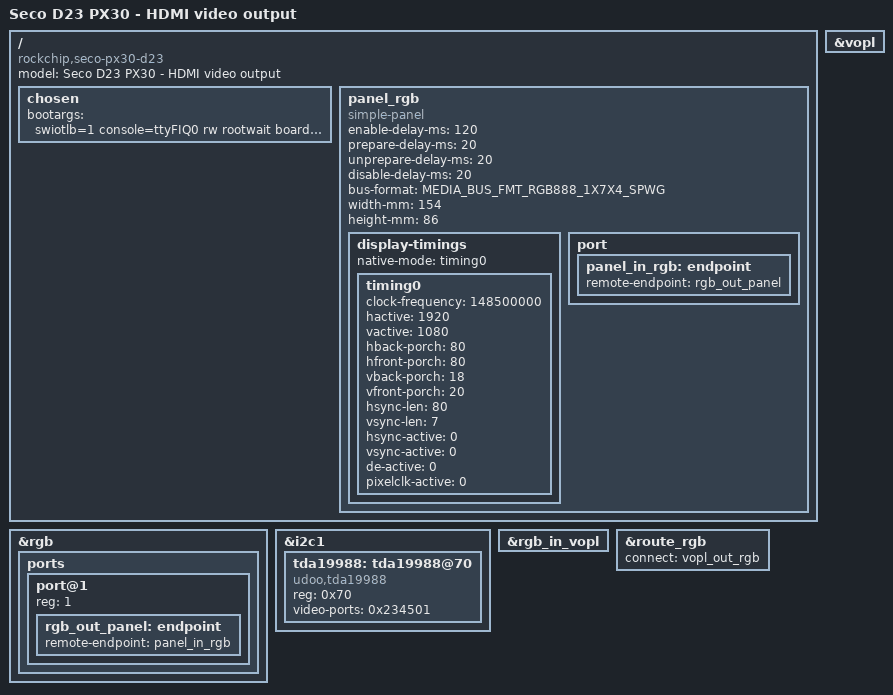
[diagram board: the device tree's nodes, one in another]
/*
 * Copyright 2020 SECO
 *
 * This program is free software; you can redistribute it and/or
 * modify it under the terms of the GNU General Public License
 * as published by the Free Software Foundation; either version 2
 * of the License, or (at your option) any later version.
 *
 * This program is distributed in the hope that it will be useful,
 * but WITHOUT ANY WARRANTY; without even the implied warranty of
 * MERCHANTABILITY or FITNESS FOR A PARTICULAR PURPOSE.  See the
 * GNU General Public License for more details.
 */

/dts-v1/;
/plugin/;

#include <dt-bindings/display/media-bus-format.h>

/ {
	model = "Seco D23 PX30 - HDMI video output";
	compatible = "rockchip,seco-px30-d23", "rockchip,px30", "rockchip,linux", "rockchip,rk3326";

/*  __________________________________________________________________________
 * |                                                                          |
 * |                                  HDMI		                        |
 * |__________________________________________________________________________|
 */

	fragment@0 {
		target-path = "/";
		__overlay__ {
			chosen {
				bootargs = "swiotlb=1 console=ttyFIQ0 rw rootwait board_revC-HDMI";
			};

			panel_rgb {
				compatible = "simple-panel";
				enable-delay-ms = <120>;
				prepare-delay-ms = <20>;
				unprepare-delay-ms = <20>;
				disable-delay-ms = <20>;
				bus-format = <MEDIA_BUS_FMT_RGB888_1X7X4_SPWG>;

				width-mm = <154>;
				height-mm = <86>;

				display-timings {
				native-mode = <&timing0>;

				timing0: timing0 {
					clock-frequency = <148500000>;
					hactive = <1920>;
					vactive = <1080>;
					hback-porch = <80>;
					hfront-porch = <80>;
					vback-porch = <18>;
					vfront-porch = <20>;
					hsync-len = <80>;
					vsync-len = <7>;
					hsync-active = <0>;
					vsync-active = <0>;
					de-active = <0>;
					pixelclk-active = <0>;
					};
				};

				port {
					panel_in_rgb: endpoint {
						remote-endpoint = <&rgb_out_panel>;
					};
				};
			};
		};
	};

	fragment@1 {
		target = <&rgb>;
		__overlay__ {
			status = "okay";
			ports {
				#address-cells = <1>;
				#size-cells = <0>;
				port@1 {
					reg = <1>;
					rgb_out_panel: endpoint {
						remote-endpoint = <&panel_in_rgb>;
					};
				};
			};
		};
	};

	fragment@2 {
		target = <&i2c1>;
		__overlay__ {
			status = "okay";
			#address-cells = <1>;
			#size-cells = <0>;

			tda19988: tda19988@70 {
				compatible = "udoo,tda19988";
				reg = <0x70>;
				video-ports = <0x234501>;
				status = "okay";
			};
		};
	};

	fragment@3 {
		target = <&rgb_in_vopl>;
		__overlay__ {
			status = "okay";
		};
	};

	fragment@4 {
		target = <&vopl>;
		__overlay__ {
			status = "okay";
		};
	};

	fragment@5 {
		target = <&route_rgb>;
		__overlay__ {
			connect = <&vopl_out_rgb>;
			status = "okay";
		};
	};
};
